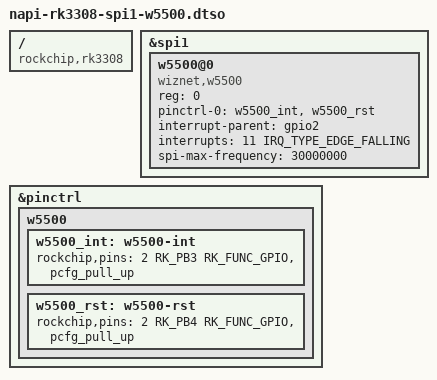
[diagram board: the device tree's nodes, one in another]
/dts-v1/;
/plugin/;

#include <dt-bindings/pinctrl/rockchip.h>
#include <dt-bindings/interrupt-controller/arm-gic.h>

/ {
	compatible = "rockchip,rk3308";

	fragment@0 {
		target = <&spi1>;
		__overlay__ {
			#address-cells = <1>;
			#size-cells = <0>;
			status = "okay";

			w5500@0 {
				compatible = "wiznet,w5500";
				reg = <0>;
				pinctrl-names = "default";
				pinctrl-0 = <&w5500_int &w5500_rst>;
				interrupt-parent = <&gpio2>;
				interrupts = <11 IRQ_TYPE_EDGE_FALLING>;
				spi-max-frequency = <30000000>;
			};
		};
	};

	fragment@1 {
		target = <&pinctrl>;
		__overlay__ {
			w5500 {
				w5500_int: w5500-int {
					rockchip,pins = <2 RK_PB3 RK_FUNC_GPIO &pcfg_pull_up>;
				};
				w5500_rst: w5500-rst {
					rockchip,pins = <2 RK_PB4 RK_FUNC_GPIO &pcfg_pull_up>;
				};
			};
		};
	};
};
